# MSS_CPSW register map
Vendor: Texas Instruments
Registers are 32-bit, read-write, no defined reset value unless marked. A register's access mark holds for its fields unless they carry their own. Offsets are as the file gives them; [hi:lo] are bit positions; {n}, {i} and the like mark numbered series; 'fields as' and 'values as' point back to an identical list.

## MSS_CPSW (part 2 of 3)
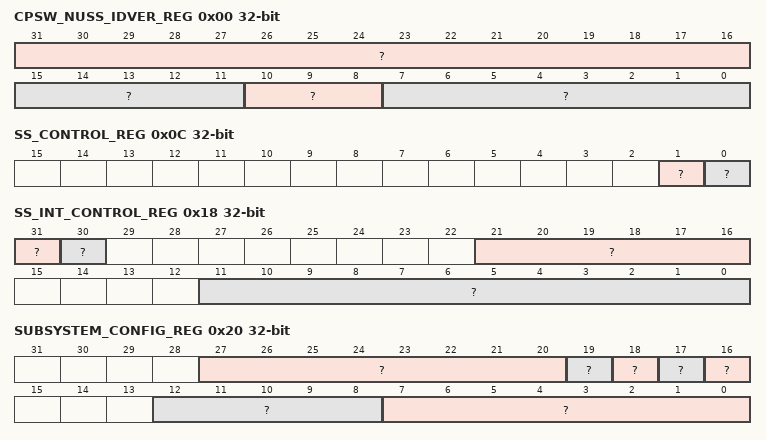
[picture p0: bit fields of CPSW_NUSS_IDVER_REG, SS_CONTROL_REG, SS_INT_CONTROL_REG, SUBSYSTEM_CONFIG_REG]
0x00 CPSW_NUSS_IDVER_REG ro — ID Version Register
  [31:16] ? — Identification value
  [15:11] ? — RTL version value
  [10:8] ? — Major version value
  [7:0] ? — Minor version value
0x04 SS_SYNCE_COUNT_REG — SS SYNCE Count Register
  [31:0] ? — Sync E Count Value
0x08 SS_SYNCE_MUX_REG — SS Synce Mux Register
  [5:0] ? — Sync E Select Value
0x0C SS_CONTROL_REG — SS Control Register
  [1] ? — Energy Efficient Enable Phy Only Mode: 0=The low power indicate state includes gating off the CPPI_GCLK to the CPSW, 1=The low power indicate state does not gate the clock to the CPSW
  [0] ? — Energy Efficient Ethernet Enable: 0=EEE is disabled, 1=EEE is enabled
0x18 SS_INT_CONTROL_REG — SS Interrupt Control Register
  [31] ? — Interrupt Test
  [30] ? — Interrupt Sel Vector Enable
  [21:16] ? — Interrupt Bypass Value
  [11:0] ? — Interrupt Prescale Value
0x1C SS_STATUS_REG ro — SS Status Register
  [0] ? — Energy Efficient Ethernet clockstop acknowledge from CPSW
0x20 SUBSYSTEM_CONFIG_REG ro — Subsystem Configuration Register
  [27:20] ? — The Number of XGMII Ports included in the CPSW_NUSS
  [19] ? — QSGMII is included in the CPSW_NUSS
  [18] ? — SGMII is included in the CPSW_NUSS
  [17] ? — RGMII is included in the CPSW_NUSS
  [16] ? — RMII is included in the CPSW_NUSS
  [12:8] ? — The number of CPTS GENF outputs
  [7:0] ? — The total number of ports including the host port 0
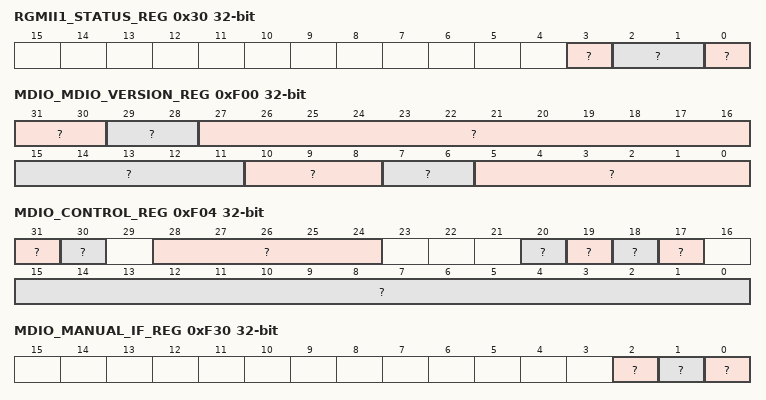
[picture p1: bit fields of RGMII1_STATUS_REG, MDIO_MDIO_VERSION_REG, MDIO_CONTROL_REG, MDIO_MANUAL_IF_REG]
0x30 RGMII1_STATUS_REG ro — RGMII1 Status Register
  [3] ? — Rgmii1 full dulex: 0=Half-duplex, 1=Full-duplex
  [2:1] ? — Rgmii1 speed: 00=10Mbps, 01=100Mbps, 10=1000Mbps, 11=reserved
  [0] ? — Rgmii1 link indicator: 0=Link is down, 1=Link is up
0xF00 MDIO_MDIO_VERSION_REG ro — MDIO Version Register
  [31:30] ? — Scheme
  [29:28] ? — bu
  [27:16] ? — Module ID
  [15:11] ? — RTL version
  [10:8] ? — Major version
  [7:6] ? — Custom version
  [5:0] ? — Minor version
0xF04 MDIO_CONTROL_REG access per field — MDIO Control Register
  [31] ? ro — MDIO state machine idle
  [30] ? rw — Enable control
  [28:24] ? ro — Highest user channel
  [20] ? rw — Preamble disable
  [19] ? rw — Fault indicator
  [18] ? rw — Fault detect enable
  [17] ? rw — Interrupt test enable
  [15:0] ? rw — Clock divider
0xF08 MDIO_ALIVE_REG — MDIO Alive Register
  [31:0] ? — MDIO alive
0xF0C MDIO_LINK_REG ro — MDIO Link Register
  [31:0] ? — MDIO link state
0xF10 MDIO_LINK_INT_RAW_REG — MDIO Link Interrupt Raw Register
  [1:0] ? — MDIO link change event raw value
0xF14 MDIO_LINK_INT_MASKED_REG — MDIO Link Interrupt Masked Register
  [1:0] ? — MDIO link change interrupt masked value
0xF18 MDIO_LINK_INT_MASK_SET_REG — MDIO Link Interrupt Mask Set Register
  [0] ? — MDIO link interrupt mask set
0xF1C MDIO_LINK_INT_MASK_CLEAR_REG — MDIO Link Interrupt Mask Clear Register
  [0] ? — MDIO link interrupt mask clear
0xF20 MDIO_USER_INT_RAW_REG — MDIO User Interrupt Raw Register
  [1:0] ? — User interrupt raw
0xF24 MDIO_USER_INT_MASKED_REG — MDIO User Interrupt Masked Register
  [1:0] ? — User interrupt masked
0xF28 MDIO_USER_INT_MASK_SET_REG — MDIO User Interrupt Mask Set Register
  [1:0] ? — MDIO user interrupt mask set
0xF2C MDIO_USER_INT_MASK_CLEAR_REG — MDIO User Interrupt Mask Clear Register
  [1:0] ? — MDIO user interrupt mask clear
0xF30 MDIO_MANUAL_IF_REG — MDIO Manual Interface Register
  [2] ? — MDIO Clock Output
  [1] ? — MDIO Output Enable
  [0] ? — MDIO Pin
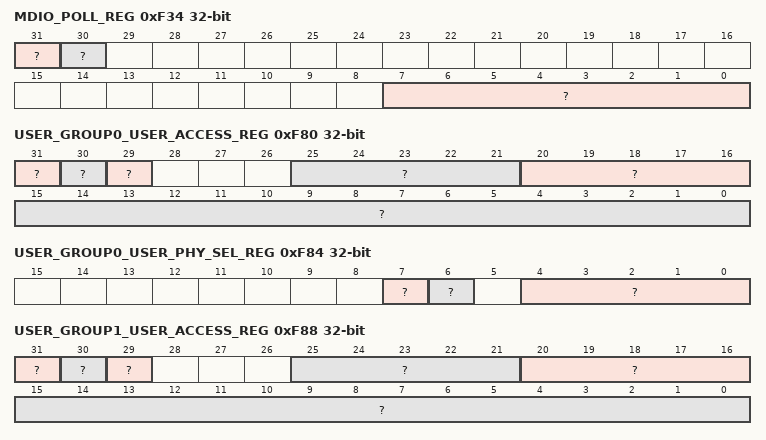
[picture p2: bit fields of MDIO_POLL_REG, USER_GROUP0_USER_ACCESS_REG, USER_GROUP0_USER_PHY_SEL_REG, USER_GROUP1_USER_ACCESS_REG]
0xF34 MDIO_POLL_REG — MDIO Poll Register
  [31] ? — MDIO Manual Mode
  [30] ? — MDIO State Change Mode
  [7:0] ? — MDIO IPG
0xF38 MDIO_POLL_EN_REG — MDIO Poll Enable Register
  [31:0] ? — MDIO Poll Enable
0xF3C MDIO_CLAUS45_REG — MDIO Clause45 Register
  [31:0] ? — MDIO Clause 45
0xF40 MDIO_USER_ADDR0_REG — MDIO Address 0 Register
  [15:0] ? — MDIO USER Address 0
0xF44 MDIO_USER_ADDR1_REG — MDIO Address 1 Register
  [15:0] ? — MDIO USER Address 1
0xF80 USER_GROUP0_USER_ACCESS_REG — MDIO User Access Register
  [31] ? — Go
  [30] ? — Write
  [29] ? — Acknowledge
  [25:21] ? — Register address
  [20:16] ? — PHY address
  [15:0] ? — User data
0xF84 USER_GROUP0_USER_PHY_SEL_REG — MDIO User PHY Select Register
  [7] ? — Link status determination select
  [6] ? — Link change interrupt enable
  [4:0] ? — PHY address whose link status is monitored
0xF88 USER_GROUP1_USER_ACCESS_REG — MDIO User Access Register
  fields as USER_GROUP0_USER_ACCESS_REG
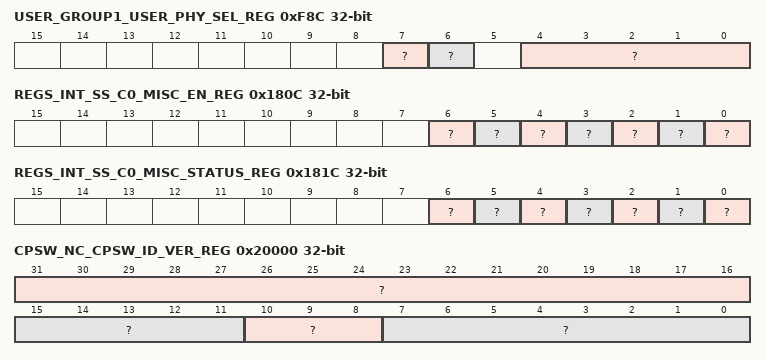
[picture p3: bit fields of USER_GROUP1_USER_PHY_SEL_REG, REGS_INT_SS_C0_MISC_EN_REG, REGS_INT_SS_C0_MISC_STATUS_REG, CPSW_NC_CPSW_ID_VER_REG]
0xF8C USER_GROUP1_USER_PHY_SEL_REG — MDIO User PHY Select Register
  fields as USER_GROUP0_USER_PHY_SEL_REG
0x1800 REGS_INT_SS_C0_TH_THRESH_PULSE_EN_REG — Core 0 THost Threshold Pulse Interrupt Enable Register
  [7:0] ? — THost Threshold Pulse Interrupt Enable Register
0x1804 REGS_INT_SS_C0_TH_PULSE_EN_REG — Core 0 THost Pulse Interrupt Enable Register
  [7:0] ?
0x1808 REGS_INT_SS_C0_FH_PULSE_EN_REG — Core 0 FHost Pulse Interrupt Enable Register
  [7:0] ?
0x180C REGS_INT_SS_C0_MISC_EN_REG — Core 0 Misc Interrupt Enable Register
  [6] ? — Core 0 MISC DED Memory Protect Error Interrupt Enable
  [5] ? — Core 0 MISC SEC Memory Protect Error Interrupt Enable
  [4] ? — Core 0 MISC CPTS Event Interrupt Enable
  [3] ? — Core 0 MISC Statistics Interrupt Enable - OR of bits n downto 0
  [2] ? — Core 0 MISC Host Interrupt Enable
  [1] ? — Core 0 MISC MDIO linkint - OR of bits 1 and 0
  [0] ? — Core 0 MISC_MDIO userint interrupt enable - OR of bits 1 and 0
0x1810 REGS_INT_SS_C0_TH_THRESH_PULSE_STATUS_REG ro — THost Threshold Pulse Interrupt Status Register
  [7:0] ? — Core 0 THost Threshold Pulse Interrupt Status Register
0x1814 REGS_INT_SS_C0_TH_PULSE_STATUS_REG ro — THost Pulse Interrupt Status Register
  [7:0] ? — Core 0 THost Pulse Interrupt Status Register
0x1818 REGS_INT_SS_C0_FH_PULSE_STATUS_REG ro — FHost Pulse Interrupt Status Register
  [7:0] ? — Core 0 FHost Pulse Interrupt Status Register
0x181C REGS_INT_SS_C0_MISC_STATUS_REG — Misc Interrupt Status Register - Set bits in this register indicate that an enabled interrupt is asserted
  [6] ? — Core 0 MISC DED Memory Protect Error Interrupt
  [5] ? — Core 0 MISC SEC Memory Protect Error Interrupt
  [4] ? — Core 0 MISC CPTS Event Interrupt
  [3] ? — Core 0 MISC Statistics Interrupt - OR of bits n downto 0
  [2] ? — Core 0 MISC Host Interrupt Enable
  [1] ? — Core 0 MISC MDIO linkint - OR of bits 1 and 0
  [0] ? — Core 0 MISC_MDIO userint interrupt - OR of bits 1 and 0
0x1820 REGS_INT_SS_C0_TH_IMAX_REG — Core 0 THost Interrupt Max Register Register
  [5:0] ?
0x1824 REGS_INT_SS_C0_FH_IMAX_REG — Core 0 FHost Interrupt Max Register Register
  [5:0] ?
0x20000 CPSW_NC_CPSW_ID_VER_REG ro — CPSW ID Version
  [31:16] ? — Identification Value
  [15:11] ? — RTL Version Value
  [10:8] ? — Major Version Value
  [7:0] ? — Minor Version Value
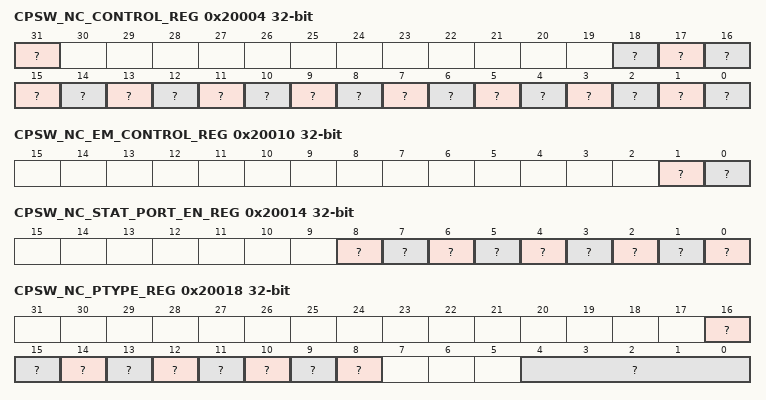
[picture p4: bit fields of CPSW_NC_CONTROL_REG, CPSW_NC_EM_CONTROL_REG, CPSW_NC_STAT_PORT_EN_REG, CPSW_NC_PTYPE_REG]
0x20004 CPSW_NC_CONTROL_REG — CPSW Switch Control
  [31] ? — ECC CRC Mode
  [18] ? — Intersperced Express Traffic enable
  [17] ? — RESERVED
  [16] ? — Energy Efficient Ethernet enable
  [15] ? — Port 0 Pass Received CRC errors
  [14] ? — Port 0 Receive Short Packet Pad
  [13] ? — Port 0 Transmit CRC remove
  [12] ? — Port 0 Transmit CRC Type
  [11] ? — Port 8 Pass Priority Tagged
  [10] ? — Port 7 Pass Priority Tagged
  [9] ? — Port 6 Pass Priority Tagged
  [8] ? — Port 5 Pass Priority Tagged
  [7] ? — Port 4 Pass Priority Tagged
  [6] ? — Port 3 Pass Priority Tagged
  [5] ? — Port 2 Pass Priority Tagged
  [4] ? — Port 1 Pass Priority Tagged
  [3] ? — Port 0 Pass Priority Tagged
  [2] ? — Port 0 Enable
  [1] ? — VLAN Aware Mode
  [0] ? — VLAN Aware Mode
0x20010 CPSW_NC_EM_CONTROL_REG — CPSW Emulation Control
  [1] ? — Emulation Soft Bit
  [0] ? — Emulation Free Bit
0x20014 CPSW_NC_STAT_PORT_EN_REG — CPSW Statistics Port Enable
  [8] ? — Port 8 Statistics Enable
  [7] ? — Port 7 Statistics Enable
  [6] ? — Port 6 Statistics Enable
  [5] ? — Port 5 Statistics Enable
  [4] ? — Port 4 Statistics Enable
  [3] ? — Port 3 Statistics Enable
  [2] ? — Port 2 Statistics Enable
  [1] ? — Port 1 Statistics Enable
  [0] ? — Port 0 Statistics Enable
0x20018 CPSW_NC_PTYPE_REG — CPSW Transmit Priority Type
  [16] ? — Port 8 Priority Type Escalate
  [15] ? — Port 7 Priority Type Escalate
  [14] ? — Port 6 Priority Type Escalate
  [13] ? — Port 5 Priority Type Escalate
  [12] ? — Port 4 Priority Type Escalate
  [11] ? — Port 3 Priority Type Escalate
  [10] ? — Port 2 Priority Type Escalate
  [9] ? — Port 1 Priority Type Escalate
  [8] ? — Port 0 Priority Type Escalate
  [4:0] ? — Escalate Priority Load Value
0x2001C CPSW_NC_SOFT_IDLE_REG — CPSW Software Idle
  [0] ? — Software Idle
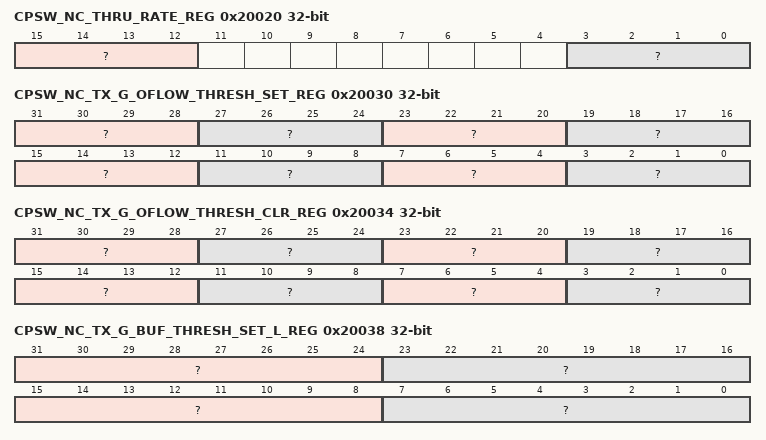
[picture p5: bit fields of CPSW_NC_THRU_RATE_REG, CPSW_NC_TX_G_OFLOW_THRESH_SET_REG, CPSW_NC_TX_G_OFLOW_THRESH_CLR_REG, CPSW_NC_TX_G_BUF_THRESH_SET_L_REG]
0x20020 CPSW_NC_THRU_RATE_REG — CPSW Thru Rate
  [15:12] ? — Switch FIFO receive through rate
  [3:0] ? — CPPI FIFO receive through rate
0x20024 CPSW_NC_GAP_THRESH_REG — CPSW Transmit FIFO Short Gap Threshold
  [4:0] ? — Short Gap Threshold
0x2002C CPSW_NC_EEE_PRESCALE_REG — CPSW Energy Efficient Ethernet Prescale Value
  [11:0] ? — Energy Efficient Ethernet Pre-scale count load value
0x20030 CPSW_NC_TX_G_OFLOW_THRESH_SET_REG — CPSW PFC Tx Global Out Flow Threshold Set
  [31:28] ? — Priority Based Flow Control Global Outflow Usage Threshold for Pri 7
  [27:24] ? — Priority Based Flow Control Global Outflow Usage Threshold for Pri 6
  [23:20] ? — Priority Based Flow Control Global Outflow Usage Threshold for Pri 5
  [19:16] ? — Priority Based Flow Control Global Outflow Usage Threshold for Pri 4
  [15:12] ? — Priority Based Flow Control Global Outflow Usage Threshold for Pri 3
  [11:8] ? — Priority Based Flow Control Global Outflow Usage Threshold for Pri 2
  [7:4] ? — Priority Based Flow Control Global Outflow Usage Threshold for Pri 1
  [3:0] ? — Priority Based Flow Control Global Outflow Usage Threshold for Pri 0
0x20034 CPSW_NC_TX_G_OFLOW_THRESH_CLR_REG — CPSW PFC Tx Global Out Flow Threshold Clear
  fields as CPSW_NC_TX_G_OFLOW_THRESH_SET_REG
0x20038 CPSW_NC_TX_G_BUF_THRESH_SET_L_REG — CPSW PFC Global Tx Buffer Threshold Set Low
  [31:24] ? — Priority Based Flow Control Global Buffer Usage Threshold for Priority 3
  [23:16] ? — Priority Based Flow Control Global Buffer Usage Threshold for Priority 2
  [15:8] ? — Priority Based Flow Control Global Buffer Usage Threshold for Priority 1
  [7:0] ? — Priority Based Flow Control Global Buffer Usage Threshold for Priority 0
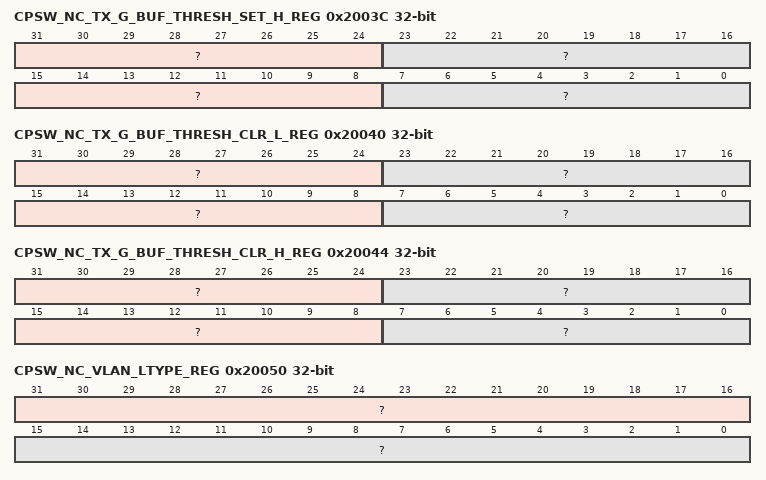
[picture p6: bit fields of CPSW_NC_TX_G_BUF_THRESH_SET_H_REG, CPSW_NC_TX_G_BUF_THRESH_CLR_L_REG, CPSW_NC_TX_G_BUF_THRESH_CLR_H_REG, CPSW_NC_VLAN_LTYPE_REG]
0x2003C CPSW_NC_TX_G_BUF_THRESH_SET_H_REG — CPSW PFC Global Tx Buffer Threshold Set High
  [31:24] ? — Priority Based Flow Control Global Buffer Usage Threshold for Priority 7
  [23:16] ? — Priority Based Flow Control Global Buffer Usage Threshold for Priority 6
  [15:8] ? — Priority Based Flow Control Global Buffer Usage Threshold for Priority 5
  [7:0] ? — Priority Based Flow Control Global Buffer Usage Threshold for Priority 4
0x20040 CPSW_NC_TX_G_BUF_THRESH_CLR_L_REG — CPSW PFC Global Tx Buffer Threshold Clear Low
  fields as CPSW_NC_TX_G_BUF_THRESH_SET_L_REG
0x20044 CPSW_NC_TX_G_BUF_THRESH_CLR_H_REG — CPSW PFC Global Tx Buffer Threshold Clear High
  fields as CPSW_NC_TX_G_BUF_THRESH_SET_H_REG
0x20050 CPSW_NC_VLAN_LTYPE_REG — VLAN Length/type
  [31:16] ? — Outer VLAN LType
  [15:0] ? — Inner VLAN LType
0x20054 CPSW_NC_EST_TS_DOMAIN_REG — Enhanced Scheduled Traffic Host Event Domain
  [7:0] ?
{0x20100+4i} CPSW_NC_TX_PRI{i}_MAXLEN_REG (i=0..7) — Transmit Priority {i} Maximum Length
  [13:0] ?
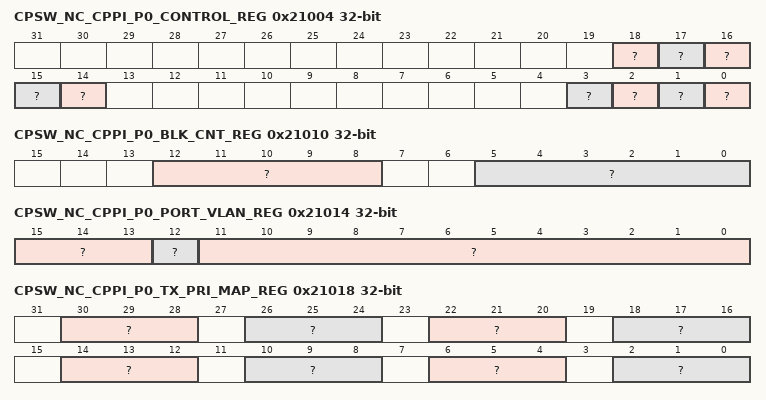
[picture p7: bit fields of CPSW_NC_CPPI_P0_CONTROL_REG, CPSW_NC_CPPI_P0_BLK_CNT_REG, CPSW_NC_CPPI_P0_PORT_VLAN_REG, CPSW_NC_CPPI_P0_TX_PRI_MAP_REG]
0x21004 CPSW_NC_CPPI_P0_CONTROL_REG — CPPI Port 0 Control
  [18] ? — Port 0 Remap DSCP_V6 Enable
  [17] ? — Port 0 Remap DSCP_V4 Enable
  [16] ? — Port 0 Remap VLAN Enable
  [15] ? — Port 0 Receive ECC Error Enable
  [14] ? — Port 0 Transmit ECC Error Enable
  [3] ? — Port 0 Transmit Checksum Enable
  [2] ? — Port 0 IPv6 DSCP enable
  [1] ? — Port 0 IPv4 DSCP enable
  [0] ? — Port 0 Receive Checksum Enable
0x21008 CPSW_NC_CPPI_P0_FLOW_ID_OFFSET_REG — CPPI Port 0 Flow ID Offset
  [13:0] ? — This value is added to the thread/Flow_ID in CPPI transmit PSI Info Word 0
0x21010 CPSW_NC_CPPI_P0_BLK_CNT_REG ro — CPPI Port 0 FIFO Block Usage Count
  [12:8] ? — Port 0 Transmit Block Count Usage
  [5:0] ? — Port 0 Receive Block Count Usage
0x21014 CPSW_NC_CPPI_P0_PORT_VLAN_REG — CPPI Port 0 VLAN
  [15:13] ? — Port VLAN Priority
  [12] ? — Port CFI bit
  [11:0] ? — Port VLAN ID
0x21018 CPSW_NC_CPPI_P0_TX_PRI_MAP_REG — CPPI Port 0 Tx Header Pri to Switch Pri Mapping
  [30:28] ? — Priority 7
  [26:24] ? — Priority 6
  [22:20] ? — Priority 5
  [18:16] ? — Priority 4
  [14:12] ? — Priority 3
  [10:8] ? — Priority 2
  [6:4] ? — Priority 1
  [2:0] ? — Priority 0
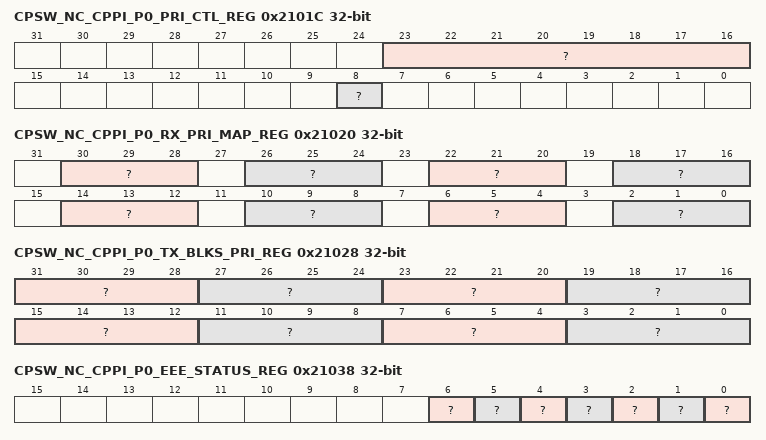
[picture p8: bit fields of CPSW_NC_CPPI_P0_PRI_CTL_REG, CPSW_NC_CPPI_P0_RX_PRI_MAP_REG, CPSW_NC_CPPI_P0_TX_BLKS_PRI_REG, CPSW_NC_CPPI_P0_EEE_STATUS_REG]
0x2101C CPSW_NC_CPPI_P0_PRI_CTL_REG — CPPI Port 0 Priority Control
  [23:16] ? — Receive Priority Based Flow Control Enable (per priority)
  [8] ? — Receive Priority Type
0x21020 CPSW_NC_CPPI_P0_RX_PRI_MAP_REG — CPPI Port 0 RX Pkt Pri to Header Pri Map
  fields as CPSW_NC_CPPI_P0_TX_PRI_MAP_REG
0x21024 CPSW_NC_CPPI_P0_RX_MAXLEN_REG — CPPI Port 0 Receive Frame Max Length
  [13:0] ? — Rx Maximum Frame Length
0x21028 CPSW_NC_CPPI_P0_TX_BLKS_PRI_REG — CPPI Port 0 Transmit Block Sub Per Priority
  [31:28] ? — Priority 7 Port Transmit Blocks
  [27:24] ? — Priority 6 Port Transmit Blocks
  [23:20] ? — Priority 5 Port Transmit Blocks
  [19:16] ? — Priority 4 Port Transmit Blocks
  [15:12] ? — Priority 3 Port Transmit Blocks
  [11:8] ? — Priority 2 Port Transmit Blocks
  [7:4] ? — Priority 1 Port Transmit Blocks
  [3:0] ? — Priority 0 Port Transmit Blocks
0x21030 CPSW_NC_CPPI_P0_IDLE2LPI_REG — Port 0 EEE Idle to LPI counter
  [23:0] ? — Port 0 EEE Idle to LPI counter load value
0x21034 CPSW_NC_CPPI_P0_LPI2WAKE_REG — Port 0 EEE LPI to wake counter
  [23:0] ? — Port 0 EEE LPI to wake counter load value
0x21038 CPSW_NC_CPPI_P0_EEE_STATUS_REG ro — Port 0 EEE status
  [6] ? — CPPI port 0 transmit FIFO (switch egress) is empty - contains no packets
  [5] ? — CPPI port 0 receive FIFO (switch ingress) is empty - contains no packets
  [4] ? — CPPI port 0 transmit FIFO hold - asserted in the LPI state and during the LPI2WAKE count time
  [3] ? — CPPI port 0 transmit wakeup - asserted in the transmit LPI2WAKE count time
  [2] ? — CPPI port 0 transmit LPI state - asserted when the port 0 transmit is in the LPI state
  [1] ? — CPPI port 0 receive LPI state - asserted when the port 0 receive is in the LPI state
  [0] ? — CPPI port 0 wait idle to LPI - asserted when port 0 is counting the IDLE2LPI time
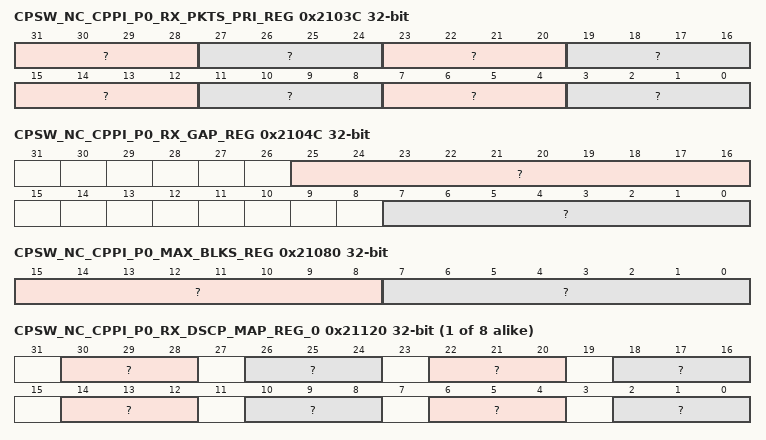
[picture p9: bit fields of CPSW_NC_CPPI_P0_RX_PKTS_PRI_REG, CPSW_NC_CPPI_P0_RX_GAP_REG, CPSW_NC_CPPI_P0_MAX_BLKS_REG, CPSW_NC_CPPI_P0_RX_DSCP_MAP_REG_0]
0x2103C CPSW_NC_CPPI_P0_RX_PKTS_PRI_REG — CPPI Port Receive Packets per priority
  [31:28] ? — Priority 7 Port Port 0 Receive Packets
  [27:24] ? — Priority 6 Port Port 0 Receive Packets
  [23:20] ? — Priority 5 Port Port 0 Receive Packets
  [19:16] ? — Priority 4 Port Port 0 Receive Packets
  [15:12] ? — Priority 3 Port Port 0 Receive Packets
  [11:8] ? — Priority 2 Port Port 0 Receive Packets
  [7:4] ? — Priority 1 Port Port 0 Receive Packets
  [3:0] ? — Priority 0 Port Port 0 Receive Packets
0x2104C CPSW_NC_CPPI_P0_RX_GAP_REG — Port 0 Receive Gap Register
  [25:16] ? — Port 0 Receive Gap Count
  [7:0] ? — Port 0 Receive Gap Enable
0x21050 CPSW_NC_CPPI_P0_FIFO_STATUS_REG ro — Port 0 FIFO Status
  [7:0] ?
0x21080 CPSW_NC_CPPI_P0_MAX_BLKS_REG — Port 0 FIFO Max Blocks
  [15:8] ? — Transmit FIFO maximum blocks
  [7:0] ? — Receive FIFO maximum blocks
{0x21120+4i} CPSW_NC_CPPI_P0_RX_DSCP_MAP_REG_{i} (i=0..7) — CPPI Port 0 Receive IPV4/IPV6 DSCP Map N
  [30:28] ? — A DSCP IPV4/V6 packet TOS of N*8+7 is mapped to this received priority
  [26:24] ? — A DSCP IPV4/V6 packet TOS of N*8+6 is mapped to this received priority
  [22:20] ? — A DSCP IPV4/V6 packet TOS of N*8+5 is mapped to this received priority
  [18:16] ? — A DSCP IPV4/V6 packet TOS of N*8+4 is mapped to this received priority
  [14:12] ? — A DSCP IPV4/V6 packet TOS of N*8+3 is mapped to this received priority
  [10:8] ? — A DSCP IPV4/V6 packet TOS of N*8+2 is mapped to this received priority
  [6:4] ? — A DSCP IPV4/V6 packet TOS of N*8+1 is mapped to this received priority
  [2:0] ? — A DSCP IPV4/V6 packet TOS of N*8+0 is mapped to this received priority
{0x21140+4i} CPSW_NC_CPPI_P0_PRI_CIR_REG_{i} (i=0..7) — CPPI Port 0 Rx Priority P Committed Information Rate
  [27:0] ? — Priority N CIR
{0x21160+4i} CPSW_NC_CPPI_P0_PRI_EIR_REG_{i} (i=0..7) — CPPI Port 0 Rx Priority P Excess Information Rate
  [27:0] ? — Priority N EIR
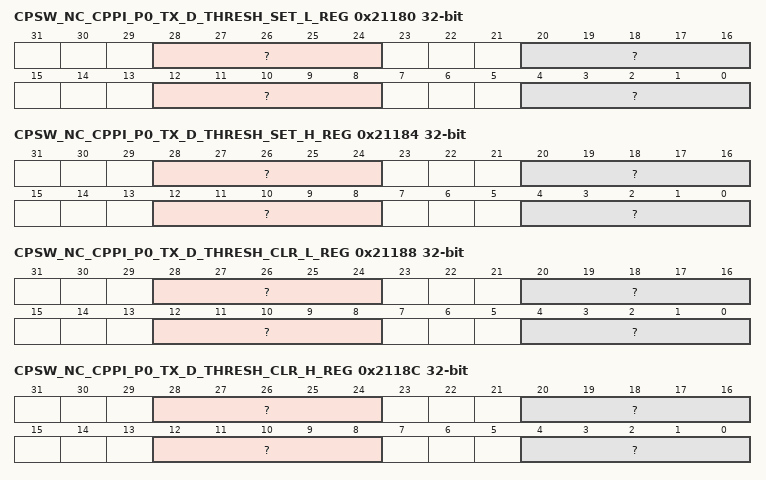
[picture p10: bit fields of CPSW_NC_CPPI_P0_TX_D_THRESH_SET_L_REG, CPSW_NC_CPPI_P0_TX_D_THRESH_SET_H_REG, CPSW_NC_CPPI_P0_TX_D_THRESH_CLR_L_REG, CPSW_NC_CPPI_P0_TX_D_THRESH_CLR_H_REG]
0x21180 CPSW_NC_CPPI_P0_TX_D_THRESH_SET_L_REG — CPPI Port 0 Tx PFC Destination Threshold Set Low
  [28:24] ? — Port Priority Based Flow Control Threshold Set Value for Priority 3
  [20:16] ? — Port Priority Based Flow Control Threshold Set Value for Priority 2
  [12:8] ? — Port Priority Based Flow Control Threshold Set Value for Priority 1
  [4:0] ? — Port Priority Based Flow Control Threshold Set Value for Priority 0
0x21184 CPSW_NC_CPPI_P0_TX_D_THRESH_SET_H_REG — CPPI Port 0 Tx PFC Destination Threshold Set High
  [28:24] ? — Port Priority Based Flow Control Threshold Set Value for Priority 7
  [20:16] ? — Port Priority Based Flow Control Threshold Set Value for Priority 6
  [12:8] ? — Port Priority Based Flow Control Threshold Set Value for Priority 5
  [4:0] ? — Port Priority Based Flow Control Threshold Set Value for Priority 4
0x21188 CPSW_NC_CPPI_P0_TX_D_THRESH_CLR_L_REG — CPPI Port 0 Tx PFC Destination Threshold Clr Low
  [28:24] ? — Port Priority Based Flow Control Threshold Clear Value for Priority 3
  [20:16] ? — Port Priority Based Flow Control Threshold Clear Value for Priority 2
  [12:8] ? — Port Priority Based Flow Control Threshold Clear Value for Priority 1
  [4:0] ? — Port Priority Based Flow Control Threshold Clear Value for Priority 0
0x2118C CPSW_NC_CPPI_P0_TX_D_THRESH_CLR_H_REG — CPPI Port 0 Tx PFC Destination Threshold Clr High
  [28:24] ? — Port Priority Based Flow Control Threshold Clear Value for Priority 7
  [20:16] ? — Port Priority Based Flow Control Threshold Clear Value for Priority 6
  [12:8] ? — Port Priority Based Flow Control Threshold Clear Value for Priority 5
  [4:0] ? — Port Priority Based Flow Control Threshold Clear Value for Priority 4
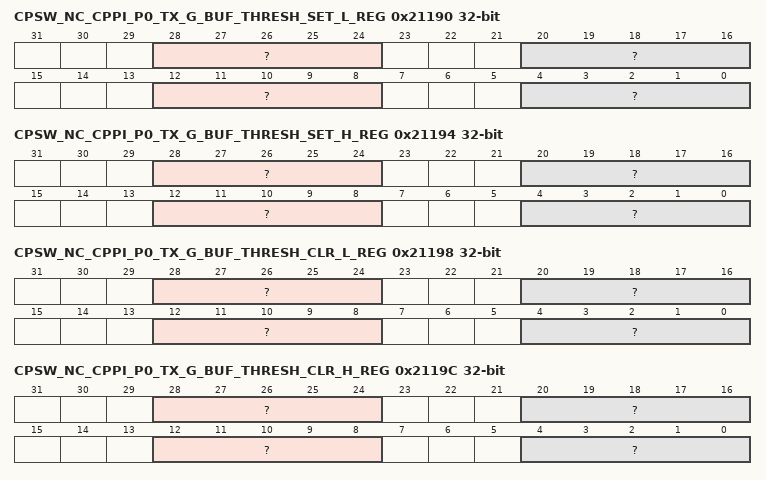
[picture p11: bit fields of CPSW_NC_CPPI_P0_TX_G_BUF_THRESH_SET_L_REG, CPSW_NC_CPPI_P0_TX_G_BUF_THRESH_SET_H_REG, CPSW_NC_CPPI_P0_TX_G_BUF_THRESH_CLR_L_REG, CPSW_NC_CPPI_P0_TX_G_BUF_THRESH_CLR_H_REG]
0x21190 CPSW_NC_CPPI_P0_TX_G_BUF_THRESH_SET_L_REG — CPPI Port 0 Tx PFC Global Buffer Threshold Set Low
  fields as CPSW_NC_CPPI_P0_TX_D_THRESH_SET_L_REG
0x21194 CPSW_NC_CPPI_P0_TX_G_BUF_THRESH_SET_H_REG — CPPI Port 0 Tx PFC Global Buffer Threshold Set High
  fields as CPSW_NC_CPPI_P0_TX_D_THRESH_SET_H_REG
0x21198 CPSW_NC_CPPI_P0_TX_G_BUF_THRESH_CLR_L_REG — CPPI Port 0 Tx PFC Global Buffer Threshold Clr Low
  fields as CPSW_NC_CPPI_P0_TX_D_THRESH_CLR_L_REG
0x2119C CPSW_NC_CPPI_P0_TX_G_BUF_THRESH_CLR_H_REG — CPPI Port 0 Tx PFC Global Buffer Threshold Clr High
  fields as CPSW_NC_CPPI_P0_TX_D_THRESH_CLR_H_REG
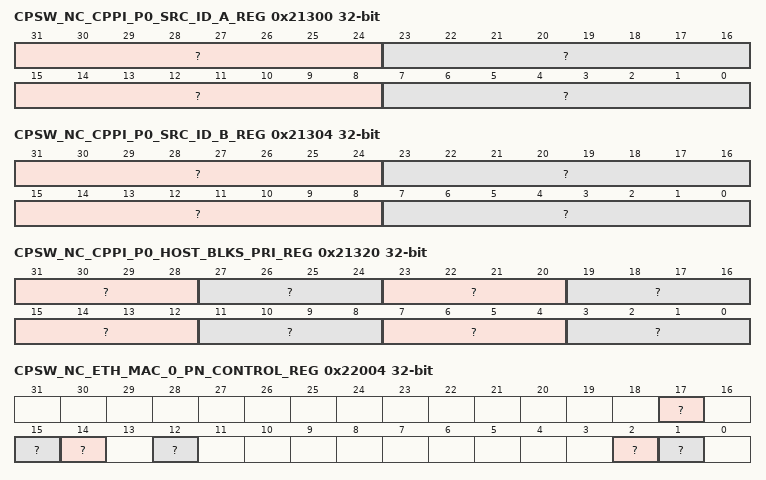
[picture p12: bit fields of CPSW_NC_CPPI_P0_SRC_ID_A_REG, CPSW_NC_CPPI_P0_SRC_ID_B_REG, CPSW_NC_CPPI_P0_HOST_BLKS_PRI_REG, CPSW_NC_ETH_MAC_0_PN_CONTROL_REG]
0x21300 CPSW_NC_CPPI_P0_SRC_ID_A_REG — CPPI Port 0 CPPI Source ID A
  [31:24] ? — Port 4 CPPI Info Word0 Source ID Value
  [23:16] ? — Port 3 CPPI Info Word0 Source ID Value
  [15:8] ? — Port 2 CPPI Info Word0 Source ID Value
  [7:0] ? — Port 1 CPPI Info Word0 Source ID Value
0x21304 CPSW_NC_CPPI_P0_SRC_ID_B_REG — CPPI Port 0 CPPI Source ID B
  [31:24] ? — Port 8 CPPI Info Word0 Source ID Value
  [23:16] ? — Port 7 CPPI Info Word0 Source ID Value
  [15:8] ? — Port 6 CPPI Info Word0 Source ID Value
  [7:0] ? — Port 5 CPPI Info Word0 Source ID Value
0x21320 CPSW_NC_CPPI_P0_HOST_BLKS_PRI_REG — CPPI Port 0 Host Blocks Priority
  [31:28] ? — Priority 7 Host Blocks
  [27:24] ? — Priority 6 Host Blocks
  [23:20] ? — Priority 5 Host Blocks
  [19:16] ? — Priority 4 Host Blocks
  [15:12] ? — Priority 3 Host Blocks
  [11:8] ? — Priority 2 Host Blocks
  [7:4] ? — Priority 1 Host Blocks
  [3:0] ? — Priority 0 Host Blocks
0x22000 CPSW_NC_ETH_MAC_0_PN_RESERVED_REG ro — Reserved
  [31:0] ? — Reserved register for memory map alignment
0x22004 CPSW_NC_ETH_MAC_0_PN_CONTROL_REG — Enet Port N Control
  [17] ? — EST Port Enable
  [15] ? — Port 0 Receive ECC Error Enable
  [14] ? — Port 0 Transmit ECC Error Enable
  [12] ? — Transmit LPI clockstop enable
  [2] ? — IPv6 DSCP enable
  [1] ? — IPv4 DSCP enable
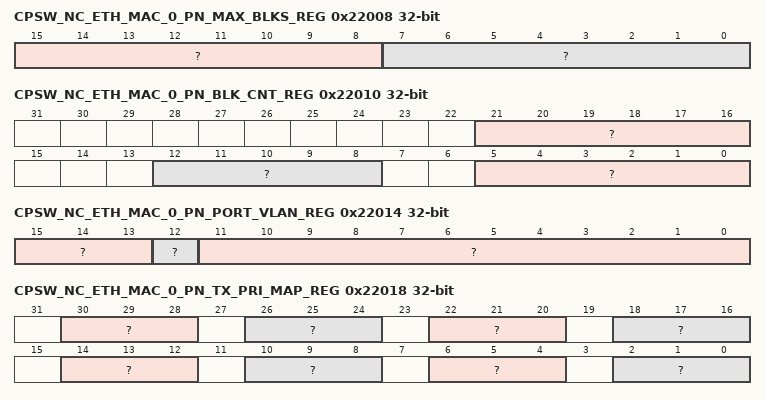
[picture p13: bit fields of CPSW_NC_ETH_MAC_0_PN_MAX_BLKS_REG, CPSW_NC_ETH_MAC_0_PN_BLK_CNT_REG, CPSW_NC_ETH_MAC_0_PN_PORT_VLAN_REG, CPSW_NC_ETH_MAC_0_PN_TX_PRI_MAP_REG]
0x22008 CPSW_NC_ETH_MAC_0_PN_MAX_BLKS_REG — Enet Port N FIFO Max Blocks
  fields as CPSW_NC_CPPI_P0_MAX_BLKS_REG
0x22010 CPSW_NC_ETH_MAC_0_PN_BLK_CNT_REG ro — Enet Port N FIFO Block Usage Count
  [21:16] ? — Receive Prempt Queue Block Count Usage
  [12:8] ? — Transmit Block Count Usage
  [5:0] ? — Receive Block Count Usage
0x22014 CPSW_NC_ETH_MAC_0_PN_PORT_VLAN_REG — Enet Port N VLAN
  fields as CPSW_NC_CPPI_P0_PORT_VLAN_REG
0x22018 CPSW_NC_ETH_MAC_0_PN_TX_PRI_MAP_REG — Enet Port N Tx Header Pri to Switch Pri Mapping
  fields as CPSW_NC_CPPI_P0_TX_PRI_MAP_REG
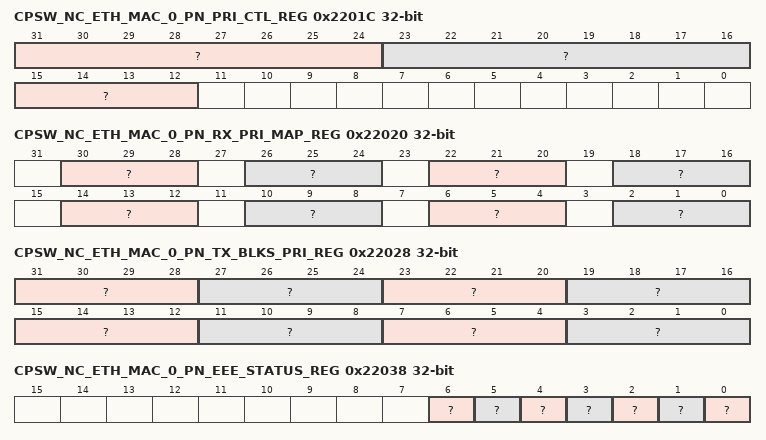
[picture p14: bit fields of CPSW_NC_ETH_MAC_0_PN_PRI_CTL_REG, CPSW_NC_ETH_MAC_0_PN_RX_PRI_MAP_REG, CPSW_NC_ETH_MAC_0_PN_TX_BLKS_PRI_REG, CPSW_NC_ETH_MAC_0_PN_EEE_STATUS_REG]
0x2201C CPSW_NC_ETH_MAC_0_PN_PRI_CTL_REG — Enet Port N Priority Control
  [31:24] ? — Transmit Priority Based Flow Control Enable (per priority)
  [23:16] ? — Receive Priority Based Flow Control Enable (per priority)
  [15:12] ? — Transmit FIFO Blocks that must be free before a non rate-limited CPPI Port 0 receive thread can begin sending a packet
0x22020 CPSW_NC_ETH_MAC_0_PN_RX_PRI_MAP_REG — Enet Port N RX Pkt Pri to Header Pri Map
  fields as CPSW_NC_CPPI_P0_TX_PRI_MAP_REG
0x22024 CPSW_NC_ETH_MAC_0_PN_RX_MAXLEN_REG — Enet Port N Receive Frame Max Length
  [13:0] ? — Rx Maximum Frame Length
0x22028 CPSW_NC_ETH_MAC_0_PN_TX_BLKS_PRI_REG — Enet Port N Transmit Block Sub Per Priority
  fields as CPSW_NC_CPPI_P0_TX_BLKS_PRI_REG
0x2202C CPSW_NC_ETH_MAC_0_PN_RX_FLOW_THRESH_REG — Enet MAC Receive Flow Threshold in Receive Buffer Words
  [8:0] ? — Receive Flow Threshold in Words
0x22030 CPSW_NC_ETH_MAC_0_PN_IDLE2LPI_REG — Enet Port N EEE Idle to LPI counter
  [23:0] ? — EEE Idle to LPI counter load value
0x22034 CPSW_NC_ETH_MAC_0_PN_LPI2WAKE_REG — Enet Port N EEE LPI to wake counter
  [23:0] ? — EEE LPI to wake counter load value
0x22038 CPSW_NC_ETH_MAC_0_PN_EEE_STATUS_REG ro — Enet Port N EEE status
  [6] ? — Transmit FIFO (switch egress) is empty - contains no packets
  [5] ? — Receive FIFO (switch ingress) is empty - contains no packets
  [4] ? — Transmit FIFO hold - asserted in the LPI state and during the LPI2WAKE count time
  [3] ? — Transmit wakeup - asserted in the transmit LPI2WAKE count time
  [2] ? — Transmit LPI state - asserted when the port 0 transmit is in the LPI state
  [1] ? — Receive LPI state - asserted when the port 0 receive is in the LPI state
  [0] ? — CPPI port 0 wait idle to LPI - asserted when port 0 is counting the IDLE2LPI time
0x22050 CPSW_NC_ETH_MAC_0_PN_FIFO_STATUS_REG ro — Enet Port N FIFO STATUS
  [18] ? — Transmit FIFO EST Buffer Active
  [17] ? — Transmit FIFO EST Address Error
  [16] ? — Transmit FIFO EST Count Error
  [15:8] ? — Transmit FIFO Express Queue Priority Allow
  [7:0] ? — Transmit FIFO Priority Active
0x22060 CPSW_NC_ETH_MAC_0_PN_EST_CONTROL_REG — Enet Port N EST CONTROL
  [25:16] ? — Transmit FIFO EST Fill Margin
  [15:9] ? — Transmit FIFO EST Prempt Comparison Value to Clear wire
  [8] ? — Transmit FIFO EST Fill Enable
  [7:5] ? — Transmit FIFO EST TimeStamp Priority
  [4] ? — Transmit FIFO EST TimeStamp One Priority
  [3] ? — Transmit FIFO EST TimeStamp First Express Packet
  [2] ? — Transmit FIFO EST TimeStamp Enable
  [1] ? — Transmit FIFO EST Buffer Select
  [0] ? — Transmit FIFO EST One Buffer
{0x22120+4i} CPSW_NC_ETH_MAC_0_PN_RX_DSCP_MAP_REG_{i} (i=0..7) — Enet Port N Receive IPV4/IPV6 DSCP Map M
  fields as CPSW_NC_CPPI_P0_RX_DSCP_MAP_REG_0
{0x22140+4i} CPSW_NC_ETH_MAC_0_PN_PRI_CIR_REG_{i} (i=0..7) — Enet Port N Rx Priority P Committed Information Rate Value
  [27:0] ? — Priority N committed information rate
{0x22160+4i} CPSW_NC_ETH_MAC_0_PN_PRI_EIR_REG_{i} (i=0..7) — Enet Port N Rx Priority P Excess Informatoin Rate Value
  [27:0] ? — Priority N Excess Information Rate count
0x22180 CPSW_NC_ETH_MAC_0_PN_TX_D_THRESH_SET_L_REG — Enet Port N Tx PFC Destination Threshold Set Low
  fields as CPSW_NC_CPPI_P0_TX_D_THRESH_SET_L_REG
0x22184 CPSW_NC_ETH_MAC_0_PN_TX_D_THRESH_SET_H_REG — Enet Port N Tx PFC Destination Threshold Set High
  fields as CPSW_NC_CPPI_P0_TX_D_THRESH_SET_H_REG
0x22188 CPSW_NC_ETH_MAC_0_PN_TX_D_THRESH_CLR_L_REG — Enet Port N Tx PFC Destination Threshold Clr Low
  fields as CPSW_NC_CPPI_P0_TX_D_THRESH_CLR_L_REG
0x2218C CPSW_NC_ETH_MAC_0_PN_TX_D_THRESH_CLR_H_REG — Enet Port N Tx PFC Destination Threshold Clr High
  fields as CPSW_NC_CPPI_P0_TX_D_THRESH_CLR_H_REG
0x22190 CPSW_NC_ETH_MAC_0_PN_TX_G_BUF_THRESH_SET_L_REG — Enet Port N Tx PFC Global Buffer Threshold Set Low
  fields as CPSW_NC_CPPI_P0_TX_D_THRESH_SET_L_REG
0x22194 CPSW_NC_ETH_MAC_0_PN_TX_G_BUF_THRESH_SET_H_REG — Enet Port N Tx PFC Global Buffer Threshold Set High
  fields as CPSW_NC_CPPI_P0_TX_D_THRESH_SET_H_REG
0x22198 CPSW_NC_ETH_MAC_0_PN_TX_G_BUF_THRESH_CLR_L_REG — Enet Port N Tx PFC Global Buffer Threshold Clr Low
  fields as CPSW_NC_CPPI_P0_TX_D_THRESH_CLR_L_REG
0x2219C CPSW_NC_ETH_MAC_0_PN_TX_G_BUF_THRESH_CLR_H_REG — Enet Port N Tx PFC Global Buffer Threshold Clr High
  fields as CPSW_NC_CPPI_P0_TX_D_THRESH_CLR_H_REG
0x22300 CPSW_NC_ETH_MAC_0_PN_TX_D_OFLOW_ADDVAL_L_REG — Enet Port N Tx Destination Out Flow Add Values Low
  [28:24] ? — Port PFC Destination Based Out Flow Add Value for Priority 3
  [20:16] ? — Port PFC Destination Based Out Flow Add Value for Priority 2
  [12:8] ? — Port PFC Destination Based Out Flow Add Value for Priority 1
  [4:0] ? — Port PFC Destination Based Out Flow Add Value for Priority 0
0x22304 CPSW_NC_ETH_MAC_0_PN_TX_D_OFLOW_ADDVAL_H_REG — Enet Port N Tx Destination Out Flow Add Values High
  [28:24] ? — Port PFC Destination Based Out Flow Add Value for Priority 7
  [20:16] ? — Port PFC Destination Based Out Flow Add Value for Priority 6
  [12:8] ? — Port PFC Destination Based Out Flow Add Value for Priority 5
  [4:0] ? — Port PFC Destination Based Out Flow Add Value for Priority 4
0x22308 CPSW_NC_ETH_MAC_0_PN_SA_L_REG — Enet Port N Tx Pause Frame Source Address Low
  [15:8] ? — Source Address Lower 8 bits
  [7:0] ? — Source Address bits 15:8
0x2230C CPSW_NC_ETH_MAC_0_PN_SA_H_REG — Enet Port N Tx Pause Frame Source Address High
  [31:24] ? — Source Address bits 23:16
  [23:16] ? — Source Address bits 31:24
  [15:8] ? — Source Address bits 39:32
  [7:0] ? — Source Address bits 47:40
0x22310 CPSW_NC_ETH_MAC_0_PN_TS_CTL_REG — Enet Port N Time Sync Control
  [31:16] ? — Time Sync Message Type Enable
  [11] ? — Time Sync Transmit Host Time Stamp Enable
  [10] ? — Time Synce Transmit Annex E Enable
  [9] ? — Time Synce Receive Annex E Enable
  [8] ? — Time Sync LTYPE 2 enable transmit and receive
  [7] ? — Time Synce Transmit Annex D Enable
  [6] ? — Time Sync Transmit VLAN LTYPE 2 enable
  [5] ? — Time Sync Transmit VLAN LTYPE 1 enable
  [4] ? — Time Synce Transmit Annex F Enable
  [3] ? — Time Synce Receive Annex D Enable
  [2] ? — Time Sync Receive VLAN LTYPE 2 enable
  [1] ? — Time Sync Receive VLAN LTYPE 1 enable
  [0] ? — Time Synce Receive Annex F Enable
0x22314 CPSW_NC_ETH_MAC_0_PN_TS_SEQ_LTYPE_REG — Enet Port N Time Sync LTYPE (and SEQ_ID_OFFSET)
  [21:16] ? — Time Sync Sequence ID Offset
  [15:0] ? — Time Sync LTYPE1
0x22318 CPSW_NC_ETH_MAC_0_PN_TS_VLAN_LTYPE_REG — Enet Port N Time Sync VLAN2 and VLAN2
  [31:16] ? — Time Sync VLAN LTYPE2
  [15:0] ? — Time Sync VLAN LTYPE1
0x2231C CPSW_NC_ETH_MAC_0_PN_TS_CTL_LTYPE2_REG — Enet Port N Time Sync Control and LTYPE 2
  [24] ? — Time Sync Unicast Enable
  [23] ? — Time Sync Time to Live Non-zero Enable
  [22] ? — Time Sync Destination IP Address 320 Enable
  [21] ? — Time Sync Destination IP Address 319 Enable
  [20] ? — Time Sync Destination IP Address 132 Enable
  [19] ? — Time Sync Destination IP Address 131 Enable
  [18] ? — Time Sync Destination IP Address 130 Enable
  [17] ? — Time Sync Destination IP Address 129 Enable
  [16] ? — Time Sync Destination IP Address 107 Enable
  [15:0] ? — Time Sync LTYPE2
0x22320 CPSW_NC_ETH_MAC_0_PN_TS_CTL2_REG — Enet Port N Time Sync Control 2
  [21:16] ? — Time Sync Domain Offset
  [15:0] ? — Time Sync Multicast Destination Address Type Enable
0x22330 CPSW_NC_ETH_MAC_0_PN_MAC_CONTROL_REG — Enet Port N Mac Control
  [24] ? — RX Copy MAC Control Frames Enable
  [23] ? — RX Copy Short Frames Enable
  [22] ? — RX Copy Error Frames Enable
  [21] ? — Transmit Short Gap Limit Enable
  [20] ? — External Transmit Flow Control Enable
  [19] ? — External Receive Flow Control Enable
  [18] ? — External Enable
  [17] ? — Gigabit Mode Force
  [16] ? — Interface Control B
  [15] ? — Interface Control A
  [12] ? — Port CRC Type
  [11] ? — Command Idle
  [10] ? — Transmit Short Gap Enable
  [7] ? — Gigabit Mode
  [6] ? — Transmit Pacing Enable
  [5] ? — GMII Enable
  [4] ? — Transmit Flow Control Enable
  [3] ? — Receive Flow Control Enable
  [2] ? — Manufacturing Test Mode
  [1] ? — Loop Back Mode
  [0] ? — Full Duplex mode
0x22334 CPSW_NC_ETH_MAC_0_PN_MAC_STATUS_REG ro — Enet Port N Mac Status
  [31] ? — cpxmac_sl IDLE
  [30] ? — Express cpxmac_sl IDLE
  [28] ? — Prempt and Express cpxmac_sl Transmit IDLE
  [27] ? — Top of receive FIFO flow control trigger occurred. This bit is write one to clear.
  [26:24] ? — The lowest priority that caused top of receive FIFO flow control trigger since the last write to clear. This field is write 0x7 to clear.
  [23:16] ? — Transmit Priority Based Flow Control Active (priority 7 down to 0)
  [15:8] ? — Receive Priority Based Flow Control Active (priority 7 down to 0)
  [6] ? — External Transmit Flow Control Enable
  [5] ? — External Receive Flow Control Enable
  [4] ? — External GIG mode
  [3] ? — External Fullduplex
  [1] ? — Receive Flow Control Active
  [0] ? — Transmit Flow Control Active
0x22338 CPSW_NC_ETH_MAC_0_PN_MAC_SOFT_RESET_REG — Enet Port N Mac Soft Reset
  [0] ? — Software reset
0x2233C CPSW_NC_ETH_MAC_0_PN_MAC_BOFFTEST_REG access per field — Enet Port N Mac Backoff Test
  [30:26] ? rw — Pacing Register Current Value
  [25:16] ? rw — Backoff Random Number Generator
  [15:12] ? ro — Collision Count
  [9:0] ? ro — Backoff Count
0x22340 CPSW_NC_ETH_MAC_0_PN_MAC_RX_PAUSETIMER_REG — Enet Port N 802.3 Receive Pause Timer
  [15:0] ? — RX Pause Timer Value
{0x22350+4i} CPSW_NC_ETH_MAC_0_PN_MAC_RXN_PAUSETIMER_REG_{i} (i=0..7) — Enet Port N PFC Priority P Rx Pause Timer
  [15:0] ? — RX Pause Timer Value
0x22370 CPSW_NC_ETH_MAC_0_PN_MAC_TX_PAUSETIMER_REG — Enet Port N 802.3 Tx Pause Timer
  [15:0] ? — TX Pause Timer Value
{0x22380+4i} CPSW_NC_ETH_MAC_0_PN_MAC_TXN_PAUSETIMER_REG_{i} (i=0..7) — Enet Port N PFC Priority P Tx Pause Timer
  [15:0] ? — TX Pause Timer Value
0x223A0 CPSW_NC_ETH_MAC_0_PN_MAC_EMCONTROL_REG — Enet Port N Emulation Control
  [1] ? — Emulation Soft Bit
  [0] ? — Emulation Free Bit
0x223A4 CPSW_NC_ETH_MAC_0_PN_MAC_TX_GAP_REG — Enet Port N Tx Inter Packet Gap
  [15:0] ? — Transmit Inter-Packet Gap
0x223A8 CPSW_NC_ETH_MAC_0_PN_MAC_PORT_CONFIG ro — Enet Port N Port Configuration
  [9] ? — IET support
  [8] ? — No XGMII support
  [7:0] ? — The number of InterVLAN routes
0x223AC CPSW_NC_ETH_MAC_0_PN_INTERVLAN_OPX_POINTER_REG — Enet Port N Tx Egress InterVLAN Operation Pointer
  [2:0] ? — InterVLAN location pointer: This field points to the InterVLAN location that will be read/written by accesses to Enet_Pn_InterVLANx_A/B.
0x223B0 CPSW_NC_ETH_MAC_0_PN_INTERVLAN_OPX_A_REG — Enet Port N Tx Egress InterVLAN A
  [31:24] ? — Destination Address bits 23:16
  [23:16] ? — Destination Address bits 31:24
  [15:8] ? — Destination Address bits 39:32
  [7:0] ? — Destination Address bits 47:40
0x223B4 CPSW_NC_ETH_MAC_0_PN_INTERVLAN_OPX_B_REG — Enet Port N Tx Egress InterVLAN B
  [31:24] ? — Source Address bits 39:32
  [23:16] ? — Source Address bits 47:40
  [15:8] ? — Destination Address bits 7:0
  [7:0] ? — Destination Address bits 15:8
0x223B8 CPSW_NC_ETH_MAC_0_PN_INTERVLAN_OPX_C_REG — Enet Port N Tx Egress InterVLAN C
  [31:24] ? — Source Address bits 7:0
  [23:16] ? — Source Address bits 15:8
  [15:8] ? — Source Address bits 23:16
  [7:0] ? — Source Address bits 31:24
0x223BC CPSW_NC_ETH_MAC_0_PN_INTERVLAN_OPX_D_REG — Enet Port N Tx Egress InterVLAN D
  [15] ? — Decrement Time To Live: When set, the Time To Live (TTL) field in the header is decremented.
  [14] ? — Destination VLAN Force Untagged Egress: When set, this bit indicates that the VLAN should be removed on egress for the routed packet.
  [13] ? — Replace Destination Address and Source Address: When set this bit indicates that the routed packet destination address should be replaced by da[47:0] and the source address should be replaced by sa[47:0].
  [12] ? — Replace VLAN ID: When set this bit indicates that the VLAN ID should be replaced for the routed packet.
  [11:0] ? — VLAN ID
{0x32000+4i} CPSW_NC_EST_FETCH_LOC_{i} (i=0..127) — The Revision Register contains the ID and revision information.
  [21:0] ? — RAM Location
0x34000 CPSW_CPDMA_REGS_CPDMA_FH_IDVER_REG ro — CPDMA FHost IDVER
  [31:0] ?
0x34004 CPSW_CPDMA_REGS_CPDMA_FH_CONTROL_REG — CPDMA FHost Control Register
  [0] ? — CPDMA FHost DMA Enable
0x34008 CPSW_CPDMA_REGS_CPDMA_FH_TEARDOWN_REG — CPDMA FHost Teardown Register
  [31] ? — CPDMA FHost Teardown Ready
  [2:0] ? — CPDMA FHost Teardown Channel
0x3400C CPSW_CPDMA_REGS_CPDMA_FH_EOQ_INT — CPDMA FHost Interrupt on EOQ only Register
  [15:8] ? — CPDMA FHost Hardware Trigger Control Enable
  [7:0] ? — CPDMA FHost Interrupt on EOQ only
0x34010 CPSW_CPDMA_REGS_CPDMA_TH_IDVER_REG ro — CPDMA THost IDVER
  [31:0] ?
0x34014 CPSW_CPDMA_REGS_CPDMA_TH_CONTROL_REG — CPDMA THost Control Register
  [0] ? — CPDMA THost DMA Enable
